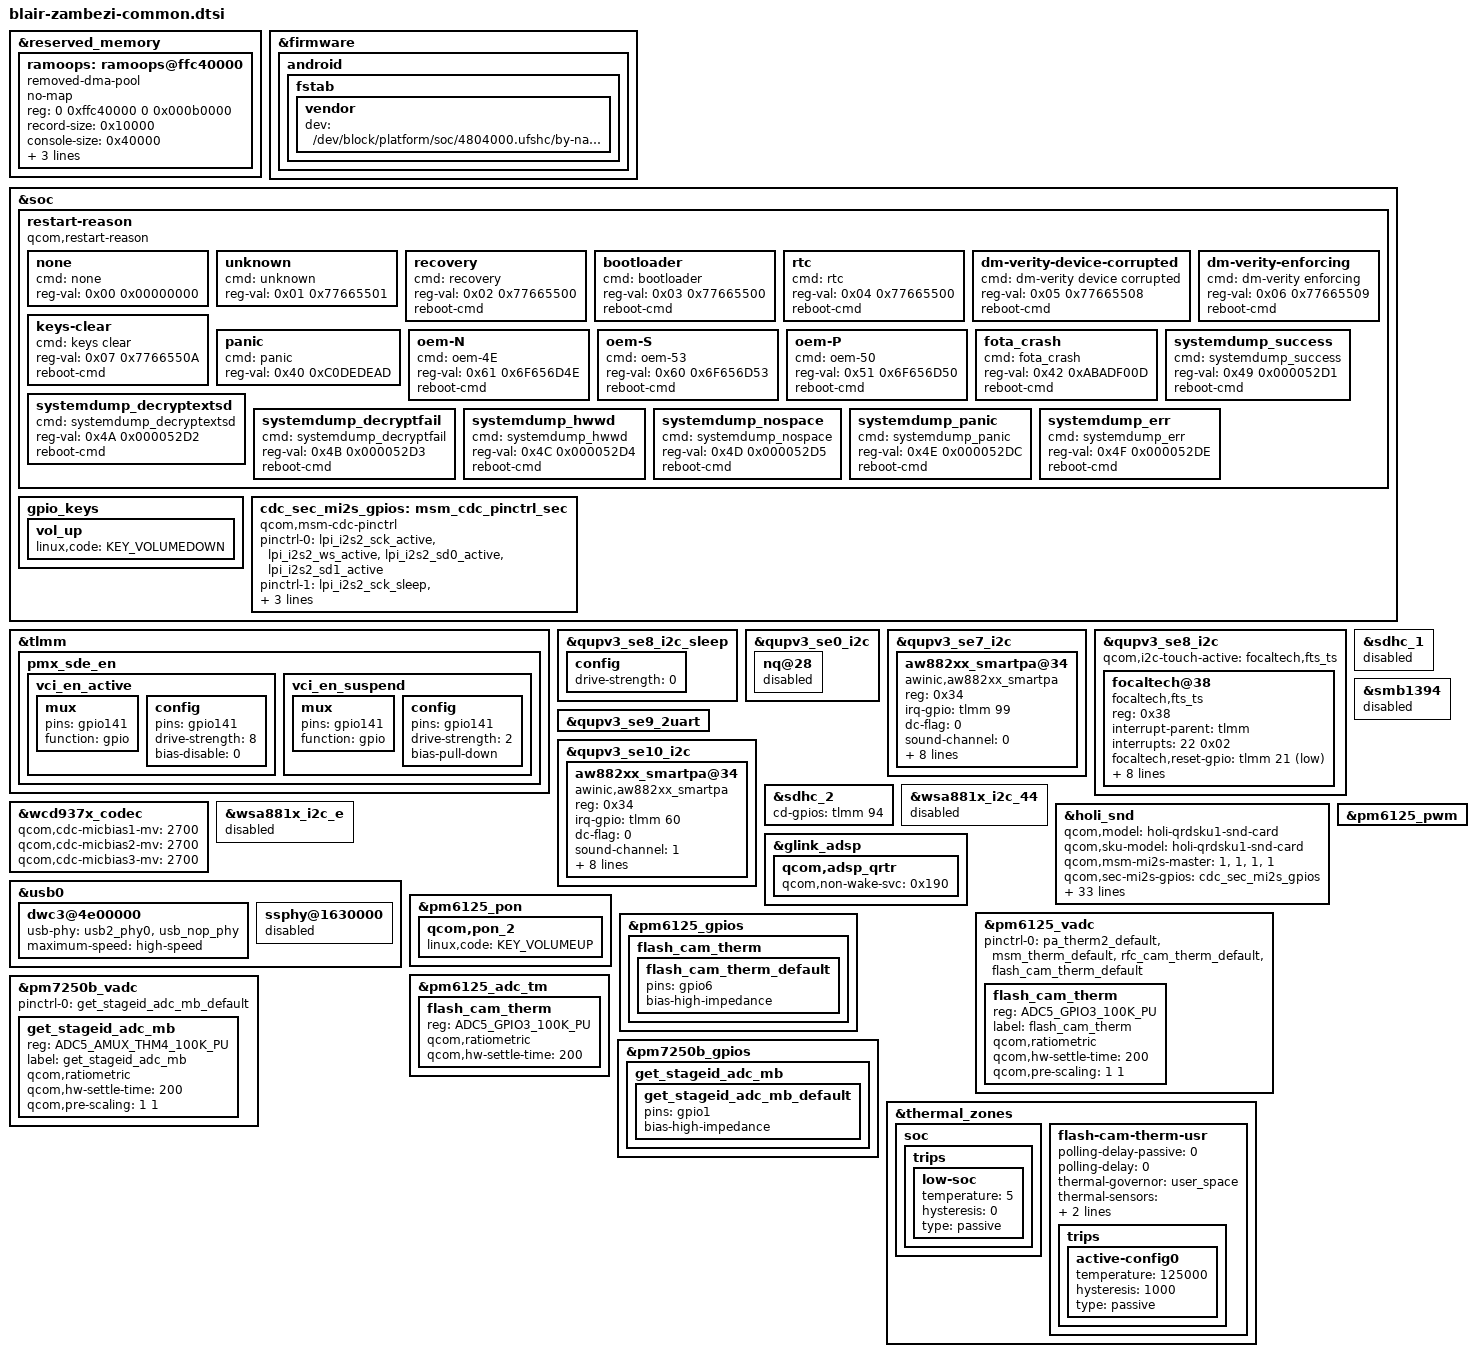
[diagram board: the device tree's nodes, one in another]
&reserved_memory {
	#address-cells = <2>;
	#size-cells = <2>;

	ramoops: ramoops@ffc40000 {
		compatible = "removed-dma-pool", "ramoops";
		no-map;
		reg = <0 0xffc40000 0 0x000b0000>;
		record-size = <0x10000>;
		console-size = <0x40000>;
		ftrace-size = <0x10000>;
		pmsg-size = <0x40000>;
		ecc-size = <16>;
	};
};

&firmware {
	android {
		fstab {
			vendor {
				dev = "/dev/block/platform/soc/4804000.ufshc/by-name/vendor";
			};
		};
	};
};

&soc {
	restart-reason {
		compatible = "qcom,restart-reason";

		none {
			cmd = "none";
			reg-val = <0x00 0x00000000>;
		};

		unknown {
			cmd = "unknown";
			reg-val = <0x01 0x77665501>;
		};

		recovery {
			cmd = "recovery";
			reg-val = <0x02 0x77665500>;
			reboot-cmd;
		};

		bootloader {
			cmd = "bootloader";
			reg-val = <0x03 0x77665500>;
			reboot-cmd;
		};

		rtc {
			cmd = "rtc";
			reg-val = <0x04 0x77665500>;
			reboot-cmd;
		};

		dm-verity-device-corrupted {
			cmd = "dm-verity device corrupted";
			reg-val = <0x05 0x77665508>;
			reboot-cmd;
		};

		dm-verity-enforcing {
			cmd = "dm-verity enforcing";
			reg-val = <0x06 0x77665509>;
			reboot-cmd;
		};

		keys-clear {
			cmd = "keys clear";
			reg-val = <0x07 0x7766550A>;
			reboot-cmd;
		};

		panic {
			cmd = "panic";
			reg-val = <0x40 0xC0DEDEAD>;
		};

		oem-N {
			cmd = "oem-4E";
			reg-val = <0x61 0x6F656D4E>;
			reboot-cmd;
		};

		oem-S {
			cmd = "oem-53";
			reg-val = <0x60 0x6F656D53>;
			reboot-cmd;
		};

		oem-P {
			cmd = "oem-50";
			reg-val = <0x51 0x6F656D50>;
			reboot-cmd;
		};

		fota_crash {
			cmd = "fota_crash";
			reg-val = <0x42 0xABADF00D>;
			reboot-cmd;
		};

		systemdump_success {
			cmd = "systemdump_success";
			reg-val = <0x49 0x000052D1>;
			reboot-cmd;
		};

		systemdump_decryptextsd {
			cmd = "systemdump_decryptextsd";
			reg-val = <0x4A 0x000052D2>;
			reboot-cmd;
		};

		systemdump_decryptfail {
			cmd = "systemdump_decryptfail";
			reg-val = <0x4B 0x000052D3>;
			reboot-cmd;
		};

		systemdump_hwwd {
			cmd = "systemdump_hwwd";
			reg-val = <0x4C 0x000052D4>;
			reboot-cmd;
		};

		systemdump_nospace {
			cmd = "systemdump_nospace";
			reg-val = <0x4D 0x000052D5>;
			reboot-cmd;
		};

		systemdump_panic {
			cmd = "systemdump_panic";
			reg-val = <0x4E 0x000052DC>;
			reboot-cmd;
		};

		systemdump_err {
			cmd = "systemdump_err";
			reg-val = <0x4F 0x000052DE>;
			reboot-cmd;
		};
	};

	gpio_keys {
		vol_up {
			linux,code = <KEY_VOLUMEDOWN>;
		};
	};

	cdc_sec_mi2s_gpios: msm_cdc_pinctrl_sec {
		compatible = "qcom,msm-cdc-pinctrl";
		pinctrl-names = "aud_active", "aud_sleep";
		pinctrl-0 = <&lpi_i2s2_sck_active &lpi_i2s2_ws_active &lpi_i2s2_sd0_active &lpi_i2s2_sd1_active>;
		pinctrl-1 = <&lpi_i2s2_sck_sleep &lpi_i2s2_ws_sleep &lpi_i2s2_sd0_sleep &lpi_i2s2_sd1_sleep>;
		qcom,lpi-gpios;
		#gpio-cells = <0>;
	};
};

&tlmm {
	pmx_sde_en: pmx_sde_en {
		vci_en_active: vci_en_active {
			mux {
				pins = "gpio141";
				function = "gpio";
			};

			config {
				pins = "gpio141";
				drive-strength = <8>; /* 8 mA */
				bias-disable = <0>; /* no pull */
			};
		};

		vci_en_suspend: vci_en_suspend {
			mux {
				pins = "gpio141";
				function = "gpio";
			};

			config {
				pins = "gpio141";
				drive-strength = <2>; /* 2 mA */
				bias-pull-down; /* PULL DOWN */
			};
		};
	};
};

&qupv3_se8_i2c_sleep {
	config {
		drive-strength = <0>;
	};
};

&qupv3_se0_i2c {
	nq@28 {
		status = "disabled";
	};
};

&qupv3_se7_i2c {
	#address-cells = <1>;
	#size-cells = <0>;
	status = "okay";

	aw882xx_smartpa@34 {
		compatible = "awinic,aw882xx_smartpa";
		reg = <0x34>;
		irq-gpio = <&tlmm 99 0>;
		dc-flag = <0>;
		sound-channel = <0>;
		rename-flag = <1>;
		aw-tx-topo-id = <0x1000ff00>;
		aw-rx-topo-id = <0x1000ff01>;
		aw-tx-port-id = <0x1003>;
		aw-rx-port-id = <0x1002>;
		aw-re-min = <4000>;
		aw-re-max= <30000>;
		aw-cali-mode = "aw_attr";
		status = "okay";
	};
};

&qupv3_se8_i2c {
	#address-cells = <1>;
	#size-cells = <0>;
	status = "okay";
	qcom,i2c-touch-active = "focaltech,fts_ts";

	focaltech@38 {
		compatible = "focaltech,fts_ts";
		reg = <0x38>;
		interrupt-parent = <&tlmm>;
		interrupts = <22 0x02>;
		focaltech,reset-gpio = <&tlmm 21 0x01>;
		focaltech,irq-gpio = <&tlmm 22 0x02>;
		focaltech,max-touch-number = <10>;
		focaltech,display-coords =  <0 0 1080 2520>;
		focaltech,avdd-gpio = <&tlmm 59 0x0>;
		pinctrl-names = "pmx_ts_active", "pmx_ts_suspend", "pmx_ts_release";
		pinctrl-0 = <&ts_active>;
		pinctrl-1 = <&ts_int_suspend &ts_reset_suspend>;
		pinctrl-2 = <&pmx_ts_release>;

		panel = <&dsi_samsung_amoled_cmd>;
	};
};

/* Debug UART Instance */
&qupv3_se9_2uart {
	status = "okay";
};

&qupv3_se10_i2c {
	#address-cells = <1>;
	#size-cells = <0>;
	status = "okay";

	aw882xx_smartpa@34 {
		compatible = "awinic,aw882xx_smartpa";
		reg = <0x34>;
		irq-gpio = <&tlmm 60 0>;
		dc-flag = <0>;
		sound-channel = <1>;
		rename-flag = <1>;
		aw-tx-topo-id = <0x1000ff00>;
		aw-rx-topo-id = <0x1000ff01>;
		aw-tx-port-id = <0x1003>;
		aw-rx-port-id = <0x1002>;
		aw-re-min = <4000>;
		aw-re-max= <30000>;
		aw-cali-mode = "aw_attr";
		status = "okay";
	};
};

&sdhc_1 {
	status = "disabled";
};

&sdhc_2 {
	cd-gpios = <&tlmm 94 GPIO_ACTIVE_HIGH>;
};

&wcd937x_codec {
	qcom,cdc-micbias1-mv = <2700>;
	qcom,cdc-micbias2-mv = <2700>;
	qcom,cdc-micbias3-mv = <2700>;
};

&wsa881x_i2c_44 {
	status = "disabled";
};

&wsa881x_i2c_e {
	status = "disabled";
};

&holi_snd {
	qcom,model = "holi-qrdsku1-snd-card";
	qcom,sku-model = "holi-qrdsku1-snd-card";
	qcom,msm-mi2s-master = <1>, <1>, <1>, <1>;
	qcom,sec-mi2s-gpios =<&cdc_sec_mi2s_gpios>;
	qcom,wcn-btfm = <1>;
	qcom,audio-routing =
		"AMIC1", "Analog Mic1",
		"Analog Mic1", "MIC BIAS1",
		"AMIC2", "Analog Mic2",
		"Analog Mic2", "MIC BIAS2",
		"AMIC3", "Analog Mic3",
		"Analog Mic3", "MIC BIAS3",
		"TX DMIC0", "Digital Mic0",
		"TX DMIC0", "MIC BIAS1",
		"TX DMIC1", "Digital Mic1",
		"TX DMIC1", "MIC BIAS1",
		"TX DMIC2", "Digital Mic2",
		"TX DMIC2", "MIC BIAS3",
		"TX DMIC3", "Digital Mic3",
		"TX DMIC3", "MIC BIAS3",
		"IN1_HPHL", "HPHL_OUT",
		"IN2_HPHR", "HPHR_OUT",
		"IN3_AUX", "AUX_OUT",
		"RX_TX DEC0_INP", "TX DEC0 MUX",
		"RX_TX DEC1_INP", "TX DEC1 MUX",
		"RX_TX DEC2_INP", "TX DEC2 MUX",
		"RX_TX DEC3_INP", "TX DEC3 MUX",
		"TX SWR_INPUT", "WCD_TX_OUTPUT",
		"VA SWR_INPUT", "VA_SWR_CLK",
		"VA SWR_INPUT", "WCD_TX_OUTPUT",
		"VA_AIF1 CAP", "VA_SWR_CLK",
		"VA_AIF2 CAP", "VA_SWR_CLK",
		"VA_AIF3 CAP", "VA_SWR_CLK",
		"VA DMIC0", "Digital Mic0",
		"VA DMIC1", "Digital Mic1",
		"VA DMIC2", "Digital Mic2",
		"VA DMIC3", "Digital Mic3",
		"VA DMIC4", "Digital Mic4",
		"VA DMIC5", "Digital Mic5",
		"VA DMIC0", "VA MIC BIAS1",
		"VA DMIC1", "VA MIC BIAS1",
		"VA DMIC2", "VA MIC BIAS3",
		"VA DMIC3", "VA MIC BIAS3";
	qcom,msm-mbhc-hphl-swh = <1>;
	qcom,msm-mbhc-gnd-swh = <1>;
	qcom,cdc-dmic01-gpios = <&cdc_dmic01_gpios>;
	qcom,cdc-dmic23-gpios = <&cdc_dmic23_gpios>;
	asoc-codec  = <&stub_codec>, <&bolero>,
		      <&wcd937x_codec>;
	asoc-codec-names = "msm-stub-codec.1", "bolero_codec",
			   "wcd937x_codec";
	qcom,msm_audio_ssr_devs = <&audio_apr>, <&q6core>, <&lpi_tlmm>,
				  <&bolero>;
};

&glink_adsp {
	qcom,adsp_qrtr {
		qcom,non-wake-svc = <0x190>;
	};
};

&usb0 {
	dwc3@4e00000 {
		usb-phy = <&usb2_phy0>, <&usb_nop_phy>;
		maximum-speed = "high-speed";
	};

	ssphy@1630000 {
		status = "disabled";
	};
};

&smb1394 {
	status = "disabled";
};

&pm6125_pon {
	qcom,pon_2 {
		linux,code = <KEY_VOLUMEUP>;
	};
};

&pm6125_pwm {
	status = "okay";
};

&pm6125_vadc {
	pinctrl-0 = <
			&pa_therm2_default
			&msm_therm_default
			&rfc_cam_therm_default
			&flash_cam_therm_default>;

	/delete-node/ rear_cam_flash_therm;

	flash_cam_therm {
		reg = <ADC5_GPIO3_100K_PU>;
		label = "flash_cam_therm";
		qcom,ratiometric;
		qcom,hw-settle-time = <200>;
		qcom,pre-scaling = <1 1>;
	};
};

&pm6125_gpios {
	/delete-node/ rear_cam_flash_therm;

	flash_cam_therm {
		flash_cam_therm_default: flash_cam_therm_default {
			pins = "gpio6";
			bias-high-impedance;
		};
	};
};

&pm6125_adc_tm {
	/delete-node/ rear_cam_flash_therm;

	flash_cam_therm {
		reg = <ADC5_GPIO3_100K_PU>;
		qcom,ratiometric;
		qcom,hw-settle-time = <200>;
	};
};

&pm7250b_vadc {
	pinctrl-names = "default";
	pinctrl-0 = <&get_stageid_adc_mb_default>;

	get_stageid_adc_mb {
		reg = <ADC5_AMUX_THM4_100K_PU>;
		label = "get_stageid_adc_mb";
		qcom,ratiometric;
		qcom,hw-settle-time = <200>;
		qcom,pre-scaling = <1 1>;
	};
};

&pm7250b_gpios {
	get_stageid_adc_mb {
		get_stageid_adc_mb_default: get_stageid_adc_mb_default {
			pins = "gpio1";
			bias-high-impedance;
		};
	};
};

&thermal_zones {
	/delete-node/ camera-therm-usr;

	soc {
		trips {
			low-soc {
				temperature = <5>;
				hysteresis = <0>;
				type = "passive";
			};
		};
	};

	flash-cam-therm-usr {
		polling-delay-passive = <0>;
		polling-delay = <0>;
		thermal-governor = "user_space";
		thermal-sensors = <&pm6125_adc_tm ADC5_GPIO3_100K_PU>;
		wake-capable-sensor;
		trips {
			active-config0 {
				temperature = <125000>;
				hysteresis = <1000>;
				type = "passive";
			};
		};
	};
};
